# N32H482 register map
Vendor: Nationstech Ltd.; File version: 1.0
Registers are 32-bit, read-write, reset 0x0 unless marked. A register's access mark holds for its fields unless they carry their own. Offsets are from the block's base; [hi:lo] are bit positions; {n}, {i} and the like mark numbered series; 'fields as' and 'values as' point back to an identical list.

## USB_HS_DEVICE — USB high speed device mode
Base 0x40040800
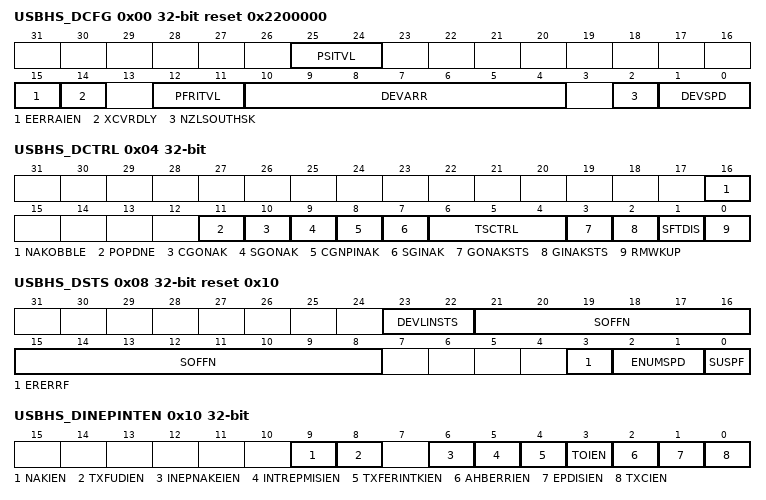
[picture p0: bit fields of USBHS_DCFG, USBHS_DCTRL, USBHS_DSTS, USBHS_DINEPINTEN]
0x00 USBHS_DCFG reset 0x2200000
  [25:24] PSITVL, [15] EERRAIEN, [14] XCVRDLY, [12:11] PFRITVL, [10:4] DEVARR, [2] NZLSOUTHSK, [1:0] DEVSPD
0x04 USBHS_DCTRL
  [16] NAKOBBLE, [11] POPDNE, [10] CGONAK wo, [9] SGONAK wo, [8] CGNPINAK wo, [7] SGINAK wo, [6:4] TSCTRL, [3] GONAKSTS ro, [2] GINAKSTS ro, [1] SFTDIS, [0] RMWKUP
0x08 USBHS_DSTS ro reset 0x10
  [23:22] DEVLINSTS, [21:8] SOFFN, [3] ERERRF, [2:1] ENUMSPD, [0] SUSPF
0x10 USBHS_DINEPINTEN
  [9] NAKIEN, [8] TXFUDIEN, [6] INEPNAKEIEN, [5] INTREPMISIEN, [4] TXFERINTKIEN, [3] TOIEN, [2] AHBERRIEN, [1] EPDISIEN, [0] TXCIEN
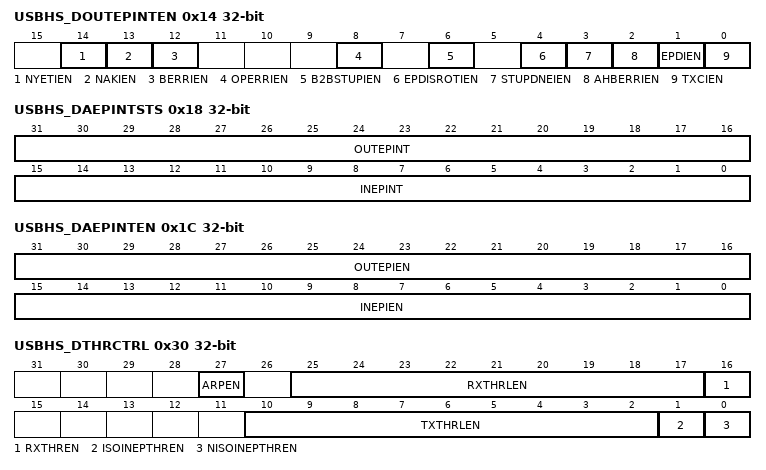
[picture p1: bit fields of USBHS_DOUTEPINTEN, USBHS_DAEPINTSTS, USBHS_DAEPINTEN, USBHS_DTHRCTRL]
0x14 USBHS_DOUTEPINTEN
  [14] NYETIEN, [13] NAKIEN, [12] BERRIEN, [8] OPERRIEN, [6] B2BSTUPIEN, [4] EPDISROTIEN, [3] STUPDNEIEN, [2] AHBERRIEN, [1] EPDIEN, [0] TXCIEN
0x18 USBHS_DAEPINTSTS ro
  [31:16] OUTEPINT, [15:0] INEPINT
0x1C USBHS_DAEPINTEN
  [31:16] OUTEPIEN, [15:0] INEPIEN
0x30 USBHS_DTHRCTRL
  [27] ARPEN, [25:17] RXTHRLEN, [16] RXTHREN, [10:2] TXTHRLEN, [1] ISOINEPTHREN, [0] NISOINEPTHREN
0x34 USBHS_DINEPFEINTEN
  [15:0] INEPTXFEIEN
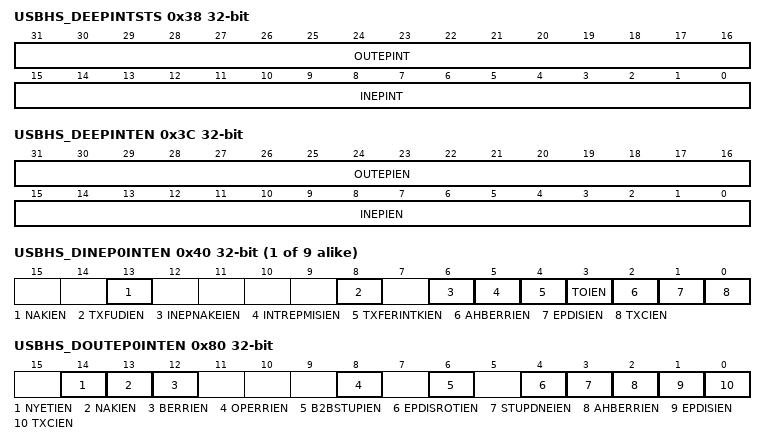
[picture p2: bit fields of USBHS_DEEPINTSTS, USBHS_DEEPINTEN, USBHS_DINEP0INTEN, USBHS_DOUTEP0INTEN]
0x38 USBHS_DEEPINTSTS
  [31:16] OUTEPINT, [15:0] INEPINT
0x3C USBHS_DEEPINTEN
  [31:16] OUTEPIEN, [15:0] INEPIEN
{0x40+4i} USBHS_DINEP{i}INTEN (i=0..8)
  [13] NAKIEN, [8] TXFUDIEN, [6] INEPNAKEIEN, [5] INTREPMISIEN, [4] TXFERINTKIEN, [3] TOIEN, [2] AHBERRIEN, [1] EPDISIEN, [0] TXCIEN
0x80 USBHS_DOUTEP0INTEN
  [14] NYETIEN, [13] NAKIEN, [12] BERRIEN, [8] OPERRIEN, [6] B2BSTUPIEN, [4] EPDISROTIEN, [3] STUPDNEIEN, [2] AHBERRIEN, [1] EPDISIEN, [0] TXCIEN
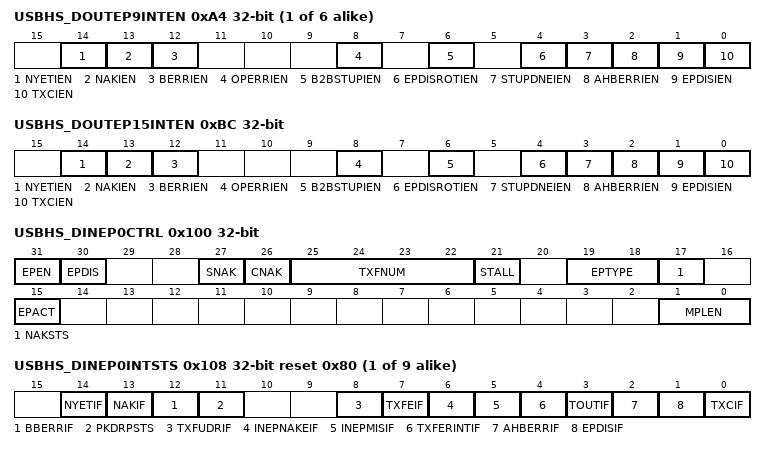
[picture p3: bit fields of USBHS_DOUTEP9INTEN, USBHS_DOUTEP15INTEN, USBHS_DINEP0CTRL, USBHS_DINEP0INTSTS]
{0x80+4i} USBHS_DOUTEP{i}INTEN (i=9..14)
  fields as USBHS_DOUTEP0INTEN
0xBC USBHS_DOUTEP15INTEN — USBHS_DOUTEP915INTEN
  fields as USBHS_DOUTEP0INTEN
0x100 USBHS_DINEP0CTRL
  [31] EPEN, [30] EPDIS, [27] SNAK wo, [26] CNAK wo, [25:22] TXFNUM, [21] STALL, [19:18] EPTYPE, [17] NAKSTS ro, [15] EPACT, [1:0] MPLEN
{0x108+0x20*i} USBHS_DINEP{i}INTSTS reset 0x80 (i=0..8)
  [14] NYETIF, [13] NAKIF, [12] BBERRIF, [11] PKDRPSTS, [8] TXFUDRIF, [7] TXFEIF ro, [6] INEPNAKEIF, [5] INEPMISIF, [4] TXFERINTIF, [3] TOUTIF, [2] AHBERRIF, [1] EPDISIF, [0] TXCIF
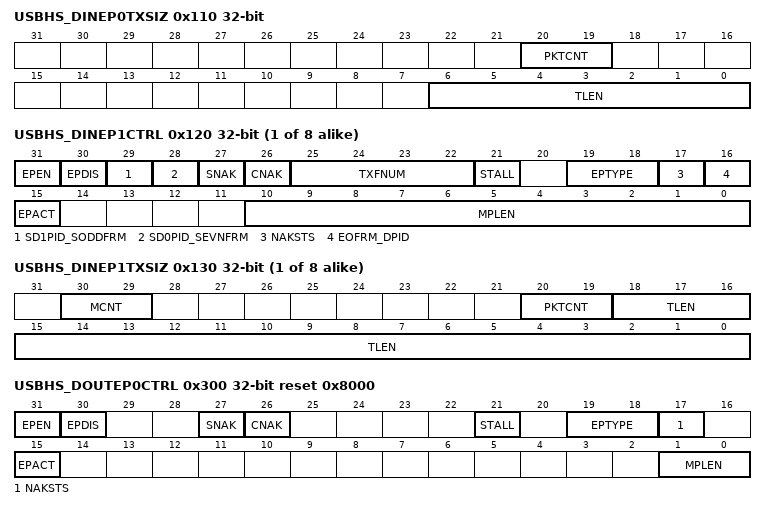
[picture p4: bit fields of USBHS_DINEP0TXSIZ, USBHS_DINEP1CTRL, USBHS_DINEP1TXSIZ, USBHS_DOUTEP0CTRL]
0x110 USBHS_DINEP0TXSIZ
  [20:19] PKTCNT, [6:0] TLEN
{0x114+0x20*i} USBHS_DINEP{i}DMADD (i=0..8)
  [31:0] DMADD
{0x118+0x20*i} USBHS_DINEP{i}TXFSTS ro (i=0..8)
  [15:0] TXFSPCAVL
{0x100+0x20*i} USBHS_DINEP{i}CTRL (i=1..8)
  [31] EPEN, [30] EPDIS, [29] SD1PID_SODDFRM wo, [28] SD0PID_SEVNFRM wo, [27] SNAK wo, [26] CNAK wo, [25:22] TXFNUM, [21] STALL, [19:18] EPTYPE, [17] NAKSTS ro, [16] EOFRM_DPID, [15] EPACT, [10:0] MPLEN
{0x110+0x20*i} USBHS_DINEP{i}TXSIZ (i=1..8)
  [30:29] MCNT, [20:19] PKTCNT, [18:0] TLEN
0x300 USBHS_DOUTEP0CTRL reset 0x8000
  [31] EPEN wo, [30] EPDIS ro, [27] SNAK wo, [26] CNAK wo, [21] STALL, [19:18] EPTYPE ro, [17] NAKSTS ro, [15] EPACT ro, [1:0] MPLEN ro
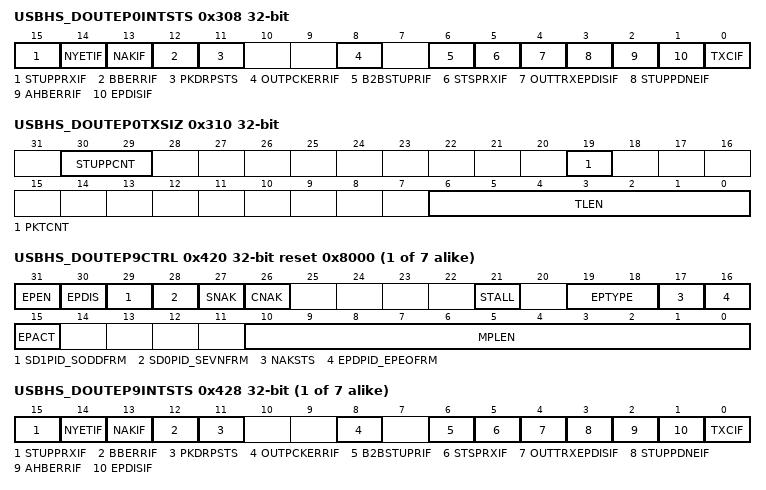
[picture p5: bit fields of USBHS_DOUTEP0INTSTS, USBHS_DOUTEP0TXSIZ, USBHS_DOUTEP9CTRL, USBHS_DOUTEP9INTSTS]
0x308 USBHS_DOUTEP0INTSTS
  [15] STUPPRXIF, [14] NYETIF, [13] NAKIF, [12] BBERRIF, [11] PKDRPSTS, [8] OUTPCKERRIF, [6] B2BSTUPRIF, [5] STSPRXIF, [4] OUTTRXEPDISIF, [3] STUPPDNEIF, [2] AHBERRIF, [1] EPDISIF, [0] TXCIF
0x310 USBHS_DOUTEP0TXSIZ
  [30:29] STUPPCNT, [19] PKTCNT, [6:0] TLEN
0x314 USBHS_DOUTEP0DMADD
  [31:0] DMADD
{0x300+0x20*i} USBHS_DOUTEP{i}CTRL reset 0x8000 (i=9..15)
  [31] EPEN wo, [30] EPDIS ro, [29] SD1PID_SODDFRM wo, [28] SD0PID_SEVNFRM wo, [27] SNAK wo, [26] CNAK wo, [21] STALL, [19:18] EPTYPE ro, [17] NAKSTS ro, [16] EPDPID_EPEOFRM ro, [15] EPACT ro, [10:0] MPLEN ro
{0x308+0x20*i} USBHS_DOUTEP{i}INTSTS (i=9..15)
  fields as USBHS_DOUTEP0INTSTS
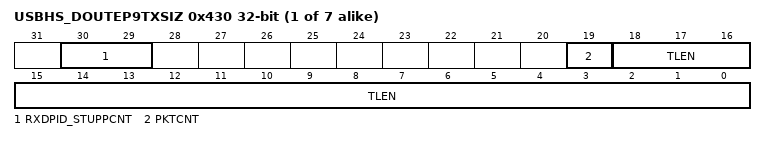
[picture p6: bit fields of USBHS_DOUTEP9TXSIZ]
{0x310+0x20*i} USBHS_DOUTEP{i}TXSIZ (i=9..15)
  [30:29] RXDPID_STUPPCNT, [19] PKTCNT, [18:0] TLEN
{0x314+0x20*i} USBHS_DOUTEP{i}DMADD (i=9..15)
  [31:0] DMADD

## USB_HS_PWRCLK — USB high speed PWR clock control
Base 0x40040E00
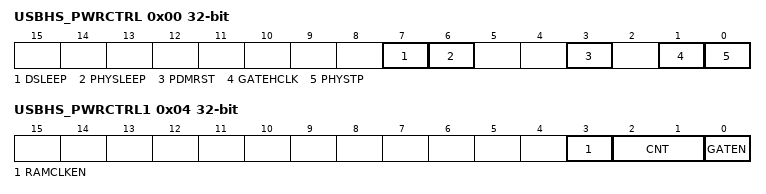
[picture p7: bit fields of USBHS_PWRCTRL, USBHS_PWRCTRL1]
0x00 USBHS_PWRCTRL
  [7] DSLEEP, [6] PHYSLEEP, [3] PDMRST, [1] GATEHCLK, [0] PHYSTP
0x04 USBHS_PWRCTRL1
  [3] RAMCLKEN, [2:1] CNT, [0] GATEN
